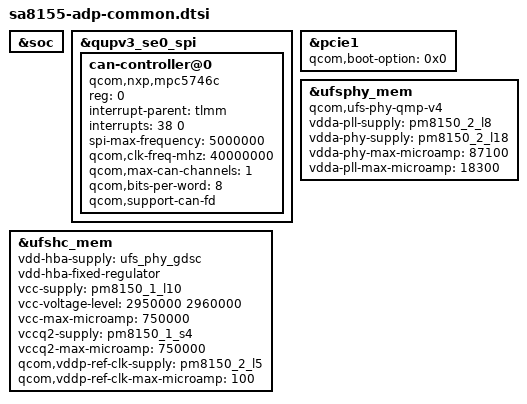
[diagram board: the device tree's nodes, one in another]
#include <dt-bindings/gpio/gpio.h>
#include <dt-bindings/input/input.h>

#include "sa8155-pmic-overlay.dtsi"
#include "sa8155-cnss.dtsi"

/* Empty node to generate minimal overlay fragment */
&soc {

};

&qupv3_se0_spi {
	status = "ok";
	#address-cells = <1>;
	#size-cells = <0>;
	can-controller@0 {
		compatible = "qcom,nxp,mpc5746c";
		reg = <0>;
		interrupt-parent = <&tlmm>;
		interrupts = <38 0>;
		spi-max-frequency = <5000000>;
		qcom,clk-freq-mhz = <40000000>;
		qcom,max-can-channels = <1>;
		qcom,bits-per-word = <8>;
		qcom,support-can-fd;
	};
};

&pcie1 {
	qcom,boot-option = <0x0>;
};

&ufsphy_mem {
	compatible = "qcom,ufs-phy-qmp-v4";

	vdda-pll-supply = <&pm8150_2_l8>;
	vdda-phy-supply = <&pm8150_2_l18>;
	vdda-phy-max-microamp = <87100>;
	vdda-pll-max-microamp = <18300>;

	status = "ok";
};

&ufshc_mem {
	vdd-hba-supply = <&ufs_phy_gdsc>;
	vdd-hba-fixed-regulator;

	vcc-supply = <&pm8150_1_l10>;
	vcc-voltage-level = <2950000 2960000>;
	vcc-max-microamp = <750000>;

	vccq2-supply = <&pm8150_1_s4>;
	vccq2-max-microamp = <750000>;

	qcom,vddp-ref-clk-supply = <&pm8150_2_l5>;
	qcom,vddp-ref-clk-max-microamp = <100>;

	status = "ok";
};
